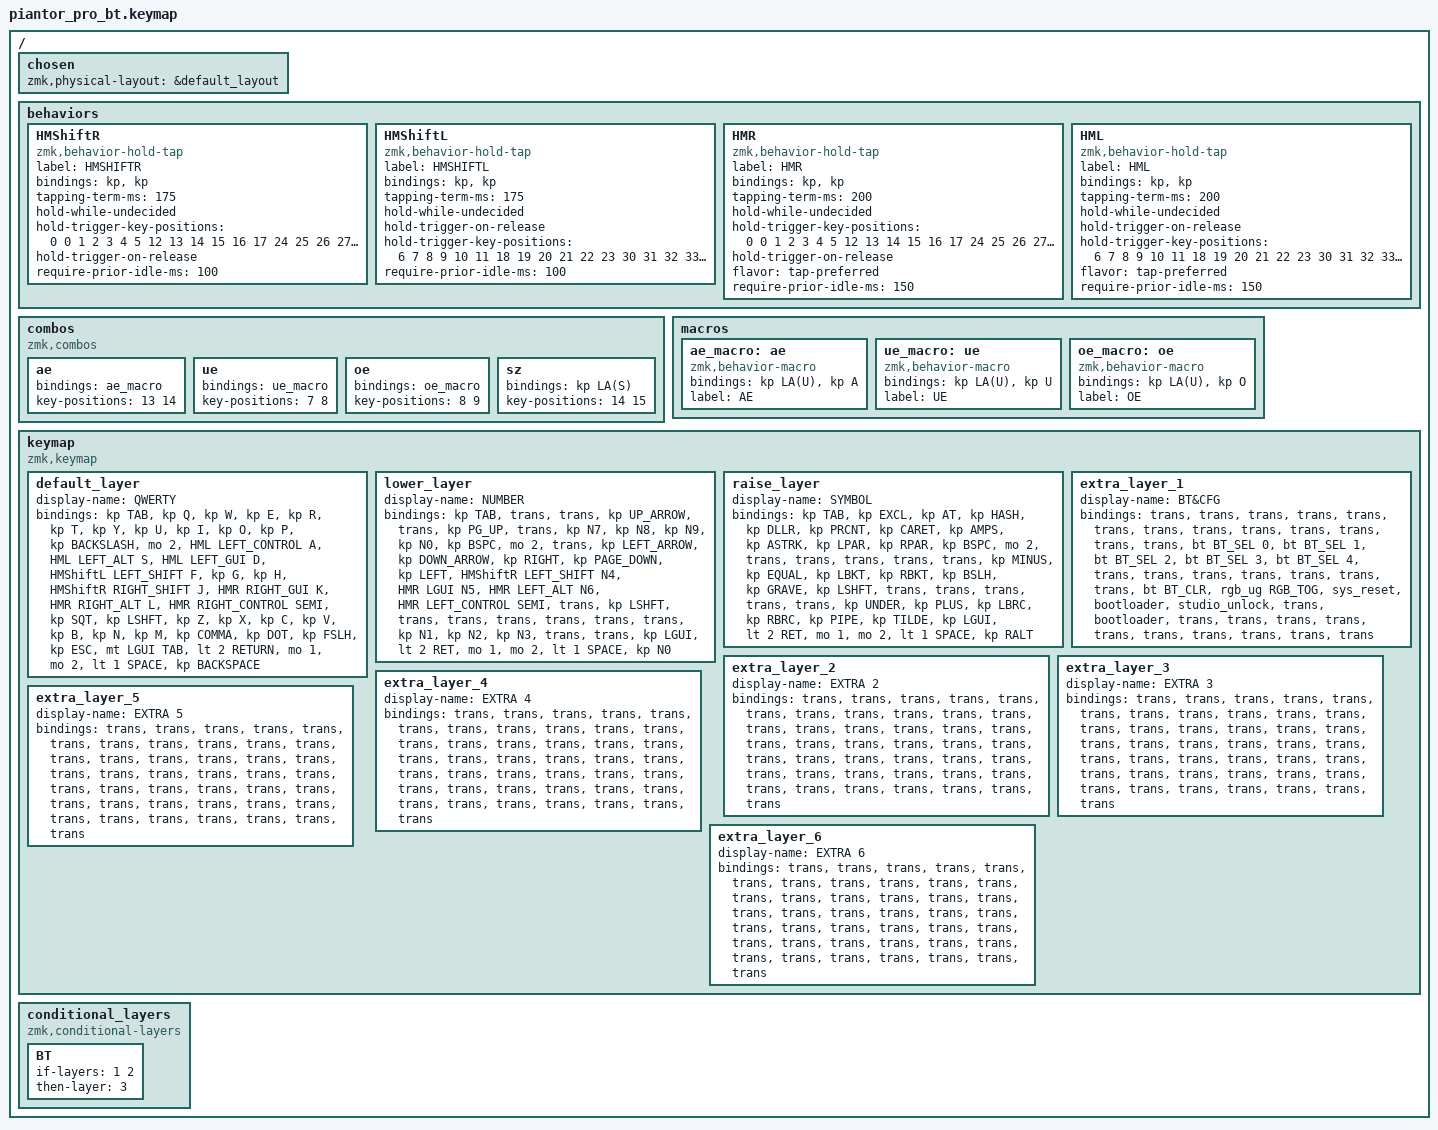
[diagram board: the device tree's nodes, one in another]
/*
 * Copyright (c) 2020 The ZMK Contributors
 *
 * SPDX-License-Identifier: MIT
 */

#include <behaviors.dtsi>
#include <dt-bindings/zmk/bt.h>
#include <dt-bindings/zmk/keys.h>
#include <dt-bindings/zmk/rgb.h>

/ {
    chosen { zmk,physical-layout = &default_layout; };
};

/ {
    behaviors {
        HMShiftR: HMShiftR {
            compatible = "zmk,behavior-hold-tap";
            label = "HMSHIFTR";
            bindings = <&kp>, <&kp>;

            #binding-cells = <2>;
            tapping-term-ms = <175>;
            hold-while-undecided;
            hold-trigger-key-positions = <0 0 1 2 3 4 5 12 13 14 15 16 17 24 25 26 27 28 29 36 37 38>;
            hold-trigger-on-release;
            require-prior-idle-ms = <100>;
        };

        HMShiftL: HMShiftL {
            compatible = "zmk,behavior-hold-tap";
            label = "HMSHIFTL";
            bindings = <&kp>, <&kp>;

            #binding-cells = <2>;
            tapping-term-ms = <175>;
            hold-while-undecided;
            hold-trigger-on-release;
            hold-trigger-key-positions = <6 7 8 9 10 11 18 19 20 21 22 23 30 31 32 33 34 35 39 40 41>;
            require-prior-idle-ms = <100>;
        };

        HMR: HMR {
            compatible = "zmk,behavior-hold-tap";
            label = "HMR";
            bindings = <&kp>, <&kp>;

            #binding-cells = <2>;
            tapping-term-ms = <200>;
            hold-while-undecided;
            hold-trigger-key-positions = <0 0 1 2 3 4 5 12 13 14 15 16 17 24 25 26 27 28 29 36 37 38>;
            hold-trigger-on-release;
            flavor = "tap-preferred";
            require-prior-idle-ms = <150>;
        };

        HML: HML {
            compatible = "zmk,behavior-hold-tap";
            label = "HML";
            bindings = <&kp>, <&kp>;

            #binding-cells = <2>;
            tapping-term-ms = <200>;
            hold-while-undecided;
            hold-trigger-on-release;
            hold-trigger-key-positions = <6 7 8 9 10 11 18 19 20 21 22 23 30 31 32 33 34 35 39 40 41>;
            flavor = "tap-preferred";
            require-prior-idle-ms = <150>;
        };
    };

    combos {
        compatible = "zmk,combos";

        ae {
            bindings = <&ae_macro>;
            key-positions = <13 14>;
        };

        ue {
            bindings = <&ue_macro>;
            key-positions = <7 8>;
        };

        oe {
            bindings = <&oe_macro>;
            key-positions = <8 9>;
        };

        sz {
            bindings = <&kp LA(S)>;
            key-positions = <14 15>;
        };
    };

    macros {
        ae_macro: ae {
            compatible = "zmk,behavior-macro";
            #binding-cells = <0>;
            bindings = <&kp LA(U) &kp A>;
            label = "AE";
        };

        ue_macro: ue {
            compatible = "zmk,behavior-macro";
            #binding-cells = <0>;
            bindings = <&kp LA(U) &kp U>;
            label = "UE";
        };

        oe_macro: oe {
            compatible = "zmk,behavior-macro";
            #binding-cells = <0>;
            bindings = <&kp LA(U) &kp O>;
            label = "OE";
        };
    };

    keymap {
        compatible = "zmk,keymap";

        default_layer {
            display-name = "QWERTY";

            // --------------------------------------------------------------------------------
            // |  TAB |  Q  |  W  |  E  |  R  |  T  |  Y  |  U   |  I  |  O  |  P  | BSPC |
            // | CTRL |  A  |  S  |  D  |  F  |  G  |  H  |  J   |  K  |  L  |  ;  |  '   |
            // | SHFT |  Z  |  X  |  C  |  V  |  B  |  N  |  M   |  ,  |  .  |  /  | ESC  |
            //                    | GUI | LWR | SPC | ENT | RSE  | ALT |

            bindings = <
&kp TAB  &kp Q  &kp W  &kp E  &kp R  &kp T  &kp Y  &kp U  &kp I  &kp O  &kp P  &kp BACKSLASH  &mo 2  &HML LEFT_CONTROL A  &HML LEFT_ALT S  &HML LEFT_GUI D  &HMShiftL LEFT_SHIFT F  &kp G  &kp H  &HMShiftR RIGHT_SHIFT J  &HMR RIGHT_GUI K  &HMR RIGHT_ALT L  &HMR RIGHT_CONTROL SEMI  &kp SQT  &kp LSHFT  &kp Z  &kp X  &kp C  &kp V  &kp B  &kp N  &kp M  &kp COMMA  &kp DOT  &kp FSLH  &kp ESC  &mt LGUI TAB  &lt 2 RETURN  &mo 1  &mo 2  &lt 1 SPACE  &kp BACKSPACE
            >;
        };

        lower_layer {
            display-name = "NUMBER";

            // -----------------------------------------------------------------------------------------
            // |  TAB |  1  |  2  |  3  |  4  |  5    |  6  |  7  |  8  |  9  |  0  | BSPC |
            // | CTRL | BT1 | BT2 | BT3 | BT4 | BT5   | LFT | DWN |  UP | RGT |     |      |
            // | SHFT | BTCR| RGB | RST | BOOT| Unlock|     |     |     |     |     |      |
            //                    | GUI |     | SPC   | ENT |     | ALT |

            bindings = <
&kp TAB  &trans  &trans  &kp UP_ARROW  &trans  &kp PG_UP  &trans  &kp N7  &kp N8  &kp N9  &kp N0  &kp BSPC  &mo 2  &trans  &kp LEFT_ARROW  &kp DOWN_ARROW  &kp RIGHT  &kp PAGE_DOWN  &kp LEFT  &HMShiftR LEFT_SHIFT N4  &HMR LGUI N5  &HMR LEFT_ALT N6  &HMR LEFT_CONTROL SEMI  &trans  &kp LSHFT  &trans  &trans  &trans  &trans  &trans  &trans  &kp N1  &kp N2  &kp N3  &trans  &trans  &kp LGUI  &lt 2 RET  &mo 1  &mo 2  &lt 1 SPACE  &kp N0
            >;
        };

        raise_layer {
            display-name = "SYMBOL";

            // -----------------------------------------------------------------------------------------
            // |  TAB |  !  |  @  |  #  |  $  |  %  |  ^  |  &  |  *  |  (  |  )  | BSPC |
            // | CTRL |     |     |     |     |     |  -  |  =  |  [  |  ]  |  \  |  `   |
            // | SHFT |     |     |     |     |     |  _  |  +  |  {  |  }  | "|" |  ~   |
            //                    | GUI |     | SPC | ENT |     | ALT |

            bindings = <
&kp TAB  &kp EXCL  &kp AT  &kp HASH  &kp DLLR  &kp PRCNT  &kp CARET  &kp AMPS  &kp ASTRK  &kp LPAR  &kp RPAR  &kp BSPC  &mo 2  &trans  &trans  &trans  &trans  &trans  &kp MINUS  &kp EQUAL  &kp LBKT  &kp RBKT  &kp BSLH  &kp GRAVE  &kp LSHFT  &trans  &trans  &trans  &trans  &trans  &kp UNDER  &kp PLUS  &kp LBRC  &kp RBRC  &kp PIPE  &kp TILDE  &kp LGUI  &lt 2 RET  &mo 1  &mo 2  &lt 1 SPACE  &kp RALT
            >;
        };

        extra_layer_1 {
            display-name = "BT&CFG";
            bindings = <
&trans  &trans  &trans  &trans  &trans  &trans  &trans  &trans  &trans  &trans  &trans  &trans  &trans  &bt BT_SEL 0  &bt BT_SEL 1  &bt BT_SEL 2  &bt BT_SEL 3  &bt BT_SEL 4  &trans  &trans  &trans  &trans  &trans  &trans  &trans  &bt BT_CLR  &rgb_ug RGB_TOG  &sys_reset  &bootloader  &studio_unlock  &trans  &bootloader  &trans  &trans  &trans  &trans  &trans  &trans  &trans  &trans  &trans  &trans
            >;
        };

        extra_layer_2 {
            display-name = "EXTRA 2";
            bindings = <
&trans  &trans  &trans  &trans  &trans  &trans  &trans  &trans  &trans  &trans  &trans  &trans  &trans  &trans  &trans  &trans  &trans  &trans  &trans  &trans  &trans  &trans  &trans  &trans  &trans  &trans  &trans  &trans  &trans  &trans  &trans  &trans  &trans  &trans  &trans  &trans  &trans  &trans  &trans  &trans  &trans  &trans
            >;
        };

        extra_layer_3 {
            display-name = "EXTRA 3";
            bindings = <
&trans  &trans  &trans  &trans  &trans  &trans  &trans  &trans  &trans  &trans  &trans  &trans  &trans  &trans  &trans  &trans  &trans  &trans  &trans  &trans  &trans  &trans  &trans  &trans  &trans  &trans  &trans  &trans  &trans  &trans  &trans  &trans  &trans  &trans  &trans  &trans  &trans  &trans  &trans  &trans  &trans  &trans
            >;
        };

        extra_layer_4 {
            display-name = "EXTRA 4";
            bindings = <
&trans  &trans  &trans  &trans  &trans  &trans  &trans  &trans  &trans  &trans  &trans  &trans  &trans  &trans  &trans  &trans  &trans  &trans  &trans  &trans  &trans  &trans  &trans  &trans  &trans  &trans  &trans  &trans  &trans  &trans  &trans  &trans  &trans  &trans  &trans  &trans  &trans  &trans  &trans  &trans  &trans  &trans
            >;
        };

        extra_layer_5 {
            display-name = "EXTRA 5";
            bindings = <
&trans  &trans  &trans  &trans  &trans  &trans  &trans  &trans  &trans  &trans  &trans  &trans  &trans  &trans  &trans  &trans  &trans  &trans  &trans  &trans  &trans  &trans  &trans  &trans  &trans  &trans  &trans  &trans  &trans  &trans  &trans  &trans  &trans  &trans  &trans  &trans  &trans  &trans  &trans  &trans  &trans  &trans
            >;
        };

        extra_layer_6 {
            display-name = "EXTRA 6";
            bindings = <
&trans  &trans  &trans  &trans  &trans  &trans  &trans  &trans  &trans  &trans  &trans  &trans  &trans  &trans  &trans  &trans  &trans  &trans  &trans  &trans  &trans  &trans  &trans  &trans  &trans  &trans  &trans  &trans  &trans  &trans  &trans  &trans  &trans  &trans  &trans  &trans  &trans  &trans  &trans  &trans  &trans  &trans
            >;
        };
    };

    conditional_layers {
        compatible = "zmk,conditional-layers";

        BT {
            if-layers = <1 2>;
            then-layer = <3>;
        };
    };
};
